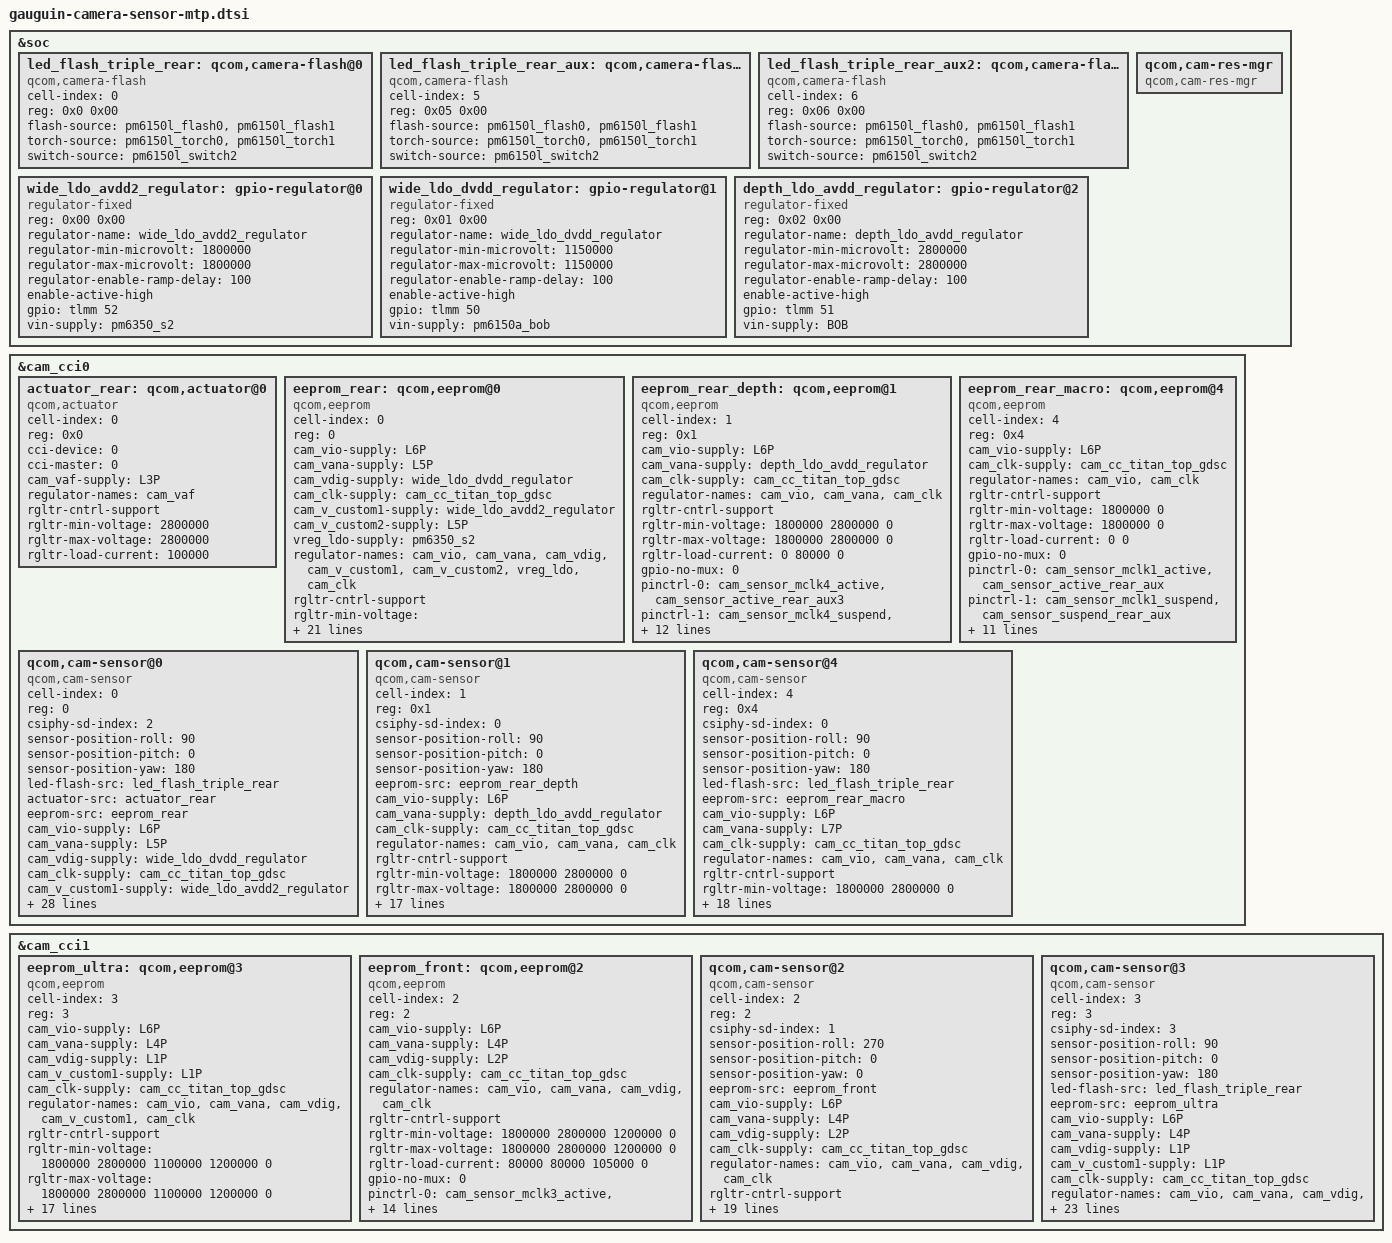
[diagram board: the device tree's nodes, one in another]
#include <dt-bindings/clock/qcom,camcc-lagoon.h>

&soc {
	led_flash_triple_rear: qcom,camera-flash@0 {
		cell-index = <0>;
		reg = <0x0 0x00>;
		compatible = "qcom,camera-flash";
		flash-source = <&pm6150l_flash0 &pm6150l_flash1>;
		torch-source = <&pm6150l_torch0 &pm6150l_torch1>;
		switch-source = <&pm6150l_switch2>;
	};

	led_flash_triple_rear_aux: qcom,camera-flash@5 {
		cell-index = <5>;
		reg = <0x05 0x00>;
		compatible = "qcom,camera-flash";
		flash-source = <&pm6150l_flash0 &pm6150l_flash1>;
		torch-source = <&pm6150l_torch0 &pm6150l_torch1>;
		switch-source = <&pm6150l_switch2>;
	};

	led_flash_triple_rear_aux2: qcom,camera-flash@6 {
		cell-index = <6>;
		reg = <0x06 0x00>;
		compatible = "qcom,camera-flash";
		flash-source = <&pm6150l_flash0 &pm6150l_flash1>;
		torch-source = <&pm6150l_torch0 &pm6150l_torch1>;
		switch-source = <&pm6150l_switch2>;
	};
	wide_ldo_avdd2_regulator: gpio-regulator@0 { //AVDD2 1.8V
		compatible = "regulator-fixed";
		reg = <0x00 0x00>;
		regulator-name = "wide_ldo_avdd2_regulator";
		regulator-min-microvolt = <1800000>;
		regulator-max-microvolt = <1800000>;
		regulator-enable-ramp-delay = <100>;
		enable-active-high;
		gpio = <&tlmm 52 0>;
		vin-supply = <&pm6350_s2>;//64M
	};
	wide_ldo_dvdd_regulator: gpio-regulator@1 { //DVDD 1.1V
		compatible = "regulator-fixed";
		reg = <0x01 0x00>;
		regulator-name = "wide_ldo_dvdd_regulator";
		regulator-min-microvolt = <1150000>;
		regulator-max-microvolt = <1150000>;
		regulator-enable-ramp-delay = <100>;
		enable-active-high;
		gpio = <&tlmm 50 0>;
		vin-supply = <&pm6150a_bob>;//64M
	};

	depth_ldo_avdd_regulator: gpio-regulator@2 { //depth AVDD 2.8V
		compatible = "regulator-fixed";
		reg = <0x02 0x00>;
		regulator-name = "depth_ldo_avdd_regulator";
		regulator-min-microvolt = <2800000>;
		regulator-max-microvolt = <2800000>;
		regulator-enable-ramp-delay = <100>;
		enable-active-high;
		gpio = <&tlmm 51 0>;
		vin-supply = <&BOB>;
	};

	qcom,cam-res-mgr {
		compatible = "qcom,cam-res-mgr";
		status = "ok";
	};
};

&cam_cci0 {
	actuator_rear: qcom,actuator@0 {
		cell-index = <0>;
		reg = <0x0>;
		compatible = "qcom,actuator";
		cci-device = <0>;
		cci-master = <0>;
		cam_vaf-supply = <&L3P>;
		regulator-names = "cam_vaf";
		rgltr-cntrl-support;
		rgltr-min-voltage = <2800000>;
		rgltr-max-voltage = <2800000>;
		rgltr-load-current = <100000>;
		status = "ok";
	};

	eeprom_rear: qcom,eeprom@0 {
		cell-index = <0>;
		reg = <0>;
		compatible = "qcom,eeprom";
		cam_vio-supply = <&L6P>;
		cam_vana-supply = <&L5P>;// AVDD 2.9V
		cam_vdig-supply = <&wide_ldo_dvdd_regulator>;
		cam_clk-supply = <&cam_cc_titan_top_gdsc>;
		cam_v_custom1-supply = <&wide_ldo_avdd2_regulator>;  //AVDD2 1.8V
		cam_v_custom2-supply = <&L5P>;  //AVDD 2.8V
                vreg_ldo-supply = <&pm6350_s2>; //npc ldo input 1.95v
		regulator-names = "cam_vio", "cam_vana", "cam_vdig",
			  "cam_v_custom1","cam_v_custom2","vreg_ldo","cam_clk";
		rgltr-cntrl-support;
		//pwm-switch;
		rgltr-min-voltage = <1800000 2900000 1150000 1800000 2800000 1950000 0>;
		rgltr-max-voltage = <1800000 2900000 1150000 1800000 2800000 2000000 0>;
		rgltr-load-current = <0 2000000 105000 80000 105000 120000 0>;
		gpio-no-mux = <0>;
		pinctrl-names = "cam_default", "cam_suspend";
		pinctrl-0 = <&cam_sensor_mclk0_active
				&cam_sensor_active_rear>;
		pinctrl-1 = <&cam_sensor_mclk0_suspend
				&cam_sensor_suspend_rear>;
		gpios = <&tlmm 29 0>,
			<&tlmm 34 0>;
		gpio-reset = <1>;
		gpio-req-tbl-num = <0 1>;
		gpio-req-tbl-flags = <1 0>;
		gpio-req-tbl-label = "CAMIF_MCLK0",
					"CAM_RESET0";
		sensor-mode = <0>;
		cci-device = <0>;
		cci-master = <0>;
		status = "ok";
		clocks = <&camcc CAM_CC_MCLK0_CLK>;
		clock-names = "cam_clk";
		clock-cntl-level = "turbo";
		clock-rates = <19200000>;
	};
    eeprom_rear_depth: qcom,eeprom@1 { //2M Depth
		cell-index = <1>;
		compatible = "qcom,eeprom";
		reg = <0x1>;
		cam_vio-supply = <&L6P>;
		cam_vana-supply = <&depth_ldo_avdd_regulator>;
		cam_clk-supply = <&cam_cc_titan_top_gdsc>;
		regulator-names = "cam_vio", "cam_vana",
			"cam_clk";
		rgltr-cntrl-support;
		//pwm-switch;
		rgltr-min-voltage = <1800000 2800000 0>;
		rgltr-max-voltage = <1800000 2800000 0>;
		rgltr-load-current = <0 80000 0>;
		gpio-no-mux = <0>;
		pinctrl-names = "cam_default", "cam_suspend";
		pinctrl-0 = <&cam_sensor_mclk4_active
				&cam_sensor_active_rear_aux3>;
		pinctrl-1 = <&cam_sensor_mclk4_suspend
				&cam_sensor_suspend_rear_aux3>;
		gpios = <&tlmm 33 0>,
			<&tlmm 38 0>;
		gpio-reset = <1>;
		gpio-req-tbl-num = <0 1>;
		gpio-req-tbl-flags = <1 0>;
		gpio-req-tbl-label = "CAMIF_MCLK4",
					"CAM_RESET4";
		sensor-mode = <0>;
		cci-device = <0>;
		cci-master = <1>;
		status = "ok";
		clocks = <&camcc CAM_CC_MCLK4_CLK>;
		clock-names = "cam_clk";
		clock-cntl-level = "turbo";
		clock-rates = <19200000>;
	};
	eeprom_rear_macro: qcom,eeprom@4 {
		cell-index = <4>;
		reg = <0x4>;
		compatible = "qcom,eeprom";
		cam_vio-supply = <&L6P>;
		//cam_vana-supply = <&L7P>;
		//cam_vdig-supply = <&L1P>;
		cam_clk-supply = <&cam_cc_titan_top_gdsc>;
		//cam_vaf-supply = <&L5P>;
		regulator-names = "cam_vio",
			"cam_clk";
		rgltr-cntrl-support;
		rgltr-min-voltage = <1800000 0>;
		rgltr-max-voltage = <1800000 0>;
		rgltr-load-current = <0 0>;
		gpio-no-mux = <0>;
		pinctrl-names = "cam_default", "cam_suspend";
		pinctrl-0 = <&cam_sensor_mclk1_active
				&cam_sensor_active_rear_aux>;
		pinctrl-1 = <&cam_sensor_mclk1_suspend
				&cam_sensor_suspend_rear_aux>;
		gpios = <&tlmm 30 0>,
			<&tlmm 35 0>;
		gpio-reset = <1>;
		gpio-req-tbl-num = <0 1>;
		gpio-req-tbl-flags = <1 0>;
		gpio-req-tbl-label = "CAMIF_MCLK1",
					"CAM_RESET1";
		sensor-mode = <0>;
		cci-device = <0>;
		cci-master = <0>;
		status = "ok";
		clocks = <&camcc CAM_CC_MCLK1_CLK>;
		clock-names = "cam_clk";
		clock-cntl-level = "turbo";
		clock-rates = <19200000>;
	};

	qcom,cam-sensor@0 { // Main
		cell-index = <0>;
		compatible = "qcom,cam-sensor";
		reg = <0>;
		csiphy-sd-index = <2>;
		sensor-position-roll = <90>;
		sensor-position-pitch = <0>;
		sensor-position-yaw = <180>;
		led-flash-src = <&led_flash_triple_rear>;
		actuator-src = <&actuator_rear>;
		eeprom-src = <&eeprom_rear>;
		cam_vio-supply = <&L6P>;
		cam_vana-supply = <&L5P>;// AVDD 2.9V
		cam_vdig-supply = <&wide_ldo_dvdd_regulator>;
		cam_clk-supply = <&cam_cc_titan_top_gdsc>;
		cam_v_custom1-supply = <&wide_ldo_avdd2_regulator>;  //AVDD2 1.8V
		cam_v_custom2-supply = <&L5P>;  //AVDD 2.8V
                vreg_ldo-supply = <&pm6350_s2>; //npc ldo input 1.95v
		regulator-names = "cam_vio", "cam_vana", "cam_vdig",
			  "cam_v_custom1","cam_v_custom2","vreg_ldo","cam_clk";
		rgltr-cntrl-support;
		//pwm-switch;
		rgltr-min-voltage = <1800000 2900000 1150000 1800000 2800000 1950000 0>;
		rgltr-max-voltage = <1800000 2900000 1150000 1800000 2800000 2000000 0>;
		rgltr-load-current = <0 2000000 105000 80000 105000 120000 0>;
		gpio-no-mux = <0>;
		pinctrl-names = "cam_default", "cam_suspend";
		pinctrl-0 = <&cam_sensor_mclk0_active
				&cam_sensor_active_rear>;
		pinctrl-1 = <&cam_sensor_mclk0_suspend
				&cam_sensor_suspend_rear>;
		gpios = <&tlmm 29 0>,
			<&tlmm 34 0>;
		gpio-reset = <1>;
		gpio-req-tbl-num = <0 1>;
		gpio-req-tbl-flags = <1 0>;
		gpio-req-tbl-label = "CAMIF_MCLK0",
					"CAM_RESET0";
		sensor-mode = <0>;
		cci-device = <0>;
		cci-master = <0>;
		status = "ok";
		clocks = <&camcc CAM_CC_MCLK0_CLK>;
		clock-names = "cam_clk";
		clock-cntl-level = "turbo";
		clock-rates = <19200000>;
	};

	qcom,cam-sensor@1 { //2M Depth
		cell-index = <1>;
		compatible = "qcom,cam-sensor";
		reg = <0x1>;
		csiphy-sd-index = <0>;
		sensor-position-roll = <90>;
		sensor-position-pitch = <0>;
		sensor-position-yaw = <180>;
		//led-flash-src = <&led_flash_triple_rear_aux>;
		//actuator-src = <&actuator_triple_rear_aux>;
		eeprom-src = <&eeprom_rear_depth>;
		cam_vio-supply = <&L6P>;
		cam_vana-supply = <&depth_ldo_avdd_regulator>;
		cam_clk-supply = <&cam_cc_titan_top_gdsc>;
		regulator-names = "cam_vio", "cam_vana",
			"cam_clk";
		rgltr-cntrl-support;
		//pwm-switch;
		rgltr-min-voltage = <1800000 2800000 0>;
		rgltr-max-voltage = <1800000 2800000 0>;
		rgltr-load-current = <0 80000 0>;
		gpio-no-mux = <0>;
		pinctrl-names = "cam_default", "cam_suspend";
		pinctrl-0 = <&cam_sensor_mclk4_active
				&cam_sensor_active_rear_aux3>;
		pinctrl-1 = <&cam_sensor_mclk4_suspend
				&cam_sensor_suspend_rear_aux3>;
		gpios = <&tlmm 33 0>,
			<&tlmm 38 0>;
		gpio-reset = <1>;
		gpio-req-tbl-num = <0 1>;
		gpio-req-tbl-flags = <1 0>;
		gpio-req-tbl-label = "CAMIF_MCLK4",
					"CAM_RESET4";
		sensor-mode = <0>;
		cci-device = <0>;
		cci-master = <1>;
		status = "ok";
		clocks = <&camcc CAM_CC_MCLK4_CLK>;
		clock-names = "cam_clk";
		clock-cntl-level = "turbo";
		clock-rates = <19200000>;
	};

	qcom,cam-sensor@4 { //For Macro
		cell-index = <4>;
		compatible = "qcom,cam-sensor";
		reg = <0x4>;
		csiphy-sd-index = <0>;
		sensor-position-roll = <90>;
		sensor-position-pitch = <0>;
		sensor-position-yaw = <180>;
		led-flash-src = <&led_flash_triple_rear>;
		//actuator-src = <&actuator_triple_rear_aux>;
		eeprom-src = <&eeprom_rear_macro>;
		cam_vio-supply = <&L6P>;
		cam_vana-supply = <&L7P>;
		//cam_vdig-supply = <&L1P>;
		cam_clk-supply = <&cam_cc_titan_top_gdsc>;
		regulator-names = "cam_vio", "cam_vana",
			"cam_clk";
		rgltr-cntrl-support;
		//pwm-switch;
		rgltr-min-voltage = <1800000 2800000 0>;
		rgltr-max-voltage = <1800000 2800000 0>;
		rgltr-load-current = <0 2000000 0>;
		gpio-no-mux = <0>;
		pinctrl-names = "cam_default", "cam_suspend";
		pinctrl-0 = <&cam_sensor_mclk1_active
			&cam_sensor_active_rear_aux>;
		pinctrl-1 = <&cam_sensor_mclk1_suspend
			&cam_sensor_suspend_rear_aux>;
		gpios = <&tlmm 30 0>,
			<&tlmm 35 0>;
		gpio-reset = <1>;
		gpio-req-tbl-num = <0 1>;
		gpio-req-tbl-flags = <1 0>;
		gpio-req-tbl-label = "CAMIF_MCLK1",
					"CAM_RESET1";
		sensor-mode = <0>;
		cci-device = <0>;
		cci-master = <0>;
		status = "ok";
		clocks = <&camcc CAM_CC_MCLK1_CLK>;
		clock-names = "cam_clk";
		clock-cntl-level = "turbo";
		clock-rates = <19200000>;
	};
};

&cam_cci1 {
	eeprom_ultra: qcom,eeprom@3 {
		cell-index = <3>;
		reg = <3>;
		compatible = "qcom,eeprom";
		cam_vio-supply = <&L6P>;
		cam_vana-supply = <&L4P>;
		cam_vdig-supply = <&L1P>;
                cam_v_custom1-supply = <&L1P>;
		cam_clk-supply = <&cam_cc_titan_top_gdsc>;
		regulator-names = "cam_vio", "cam_vana", "cam_vdig",
			   "cam_v_custom1", "cam_clk";
		rgltr-cntrl-support;
		 //pwm-switch;
		rgltr-min-voltage = <1800000 2800000 1100000 1200000 0>;
		rgltr-max-voltage = <1800000 2800000 1100000 1200000 0>;
		rgltr-load-current = <0 2000000 105000 105000 0>;
		gpio-no-mux = <0>;
		pinctrl-names = "cam_default", "cam_suspend";
		pinctrl-0 = <&cam_sensor_mclk2_active
			   &cam_sensor_active_rear_aux2>;
		pinctrl-1 = <&cam_sensor_mclk2_suspend
			   &cam_sensor_suspend_rear_aux2>;
		gpios = <&tlmm 31 0>,
			  <&tlmm 36 0>;
		gpio-reset = <1>;
		gpio-req-tbl-num = <0 1>;
		gpio-req-tbl-flags = <1 0>;
		gpio-req-tbl-label = "CAMIF_MCLK2",
					"CAM_RESET2";
		sensor-mode = <0>;
		cci-device = <1>;
		cci-master = <0>;
		status = "ok";
		clocks = <&camcc CAM_CC_MCLK2_CLK>;
		clock-names = "cam_clk";
		clock-cntl-level = "turbo";
		clock-rates = <19200000>;
	};
	eeprom_front: qcom,eeprom@2 {
		cell-index = <2>;
		reg = <2>;
		compatible = "qcom,eeprom";
		cam_vio-supply = <&L6P>;
		cam_vana-supply = <&L4P>;
		cam_vdig-supply = <&L2P>;
		cam_clk-supply = <&cam_cc_titan_top_gdsc>;
		regulator-names = "cam_vio", "cam_vana", "cam_vdig",
			   "cam_clk";
		rgltr-cntrl-support;
		 //pwm-switch;
		rgltr-min-voltage = <1800000 2800000 1200000 0>;
		rgltr-max-voltage = <1800000 2800000 1200000 0>;
		rgltr-load-current = <80000 80000 105000 0>;
		gpio-no-mux = <0>;
		pinctrl-names = "cam_default", "cam_suspend";
		pinctrl-0 = <&cam_sensor_mclk3_active
			   &cam_sensor_active_front>;
		pinctrl-1 = <&cam_sensor_mclk3_suspend
			   &cam_sensor_suspend_front>;
		gpios = <&tlmm 32 0>,
			  <&tlmm 37 0>;
		gpio-reset = <1>;
		gpio-req-tbl-num = <0 1>;
		gpio-req-tbl-flags = <1 0>;
		gpio-req-tbl-label = "CAMIF_MCLK3",
					"CAM_RESET3";
		sensor-mode = <0>;
		cci-device = <1>;
		cci-master = <0>;
		status = "ok";
		clocks = <&camcc CAM_CC_MCLK3_CLK>;
		clock-names = "cam_clk";
		clock-cntl-level = "turbo";
		clock-rates = <19200000>;
	};
	qcom,cam-sensor@2 { //16M FRONT
		cell-index = <2>;
		compatible = "qcom,cam-sensor";
		reg = <2>;
		csiphy-sd-index = <1>;
		sensor-position-roll = <270>;
		sensor-position-pitch = <0>;
		sensor-position-yaw = <0>;
		//led-flash-src = <&led_flash_triple_rear_aux>;
		//actuator-src = <&actuator_triple_rear_aux>;
		eeprom-src = <&eeprom_front>;
		cam_vio-supply = <&L6P>;
		cam_vana-supply = <&L4P>;
		cam_vdig-supply = <&L2P>;
		cam_clk-supply = <&cam_cc_titan_top_gdsc>;
		regulator-names = "cam_vio", "cam_vana", "cam_vdig",
			   "cam_clk";
		rgltr-cntrl-support;
		 //pwm-switch;
		rgltr-min-voltage = <1800000 2800000 1200000 0>;
		rgltr-max-voltage = <1800000 2800000 1200000 0>;
		rgltr-load-current = <80000 80000 105000 0>;
		gpio-no-mux = <0>;
		pinctrl-names = "cam_default", "cam_suspend";
		pinctrl-0 = <&cam_sensor_mclk3_active
			   &cam_sensor_active_front>;
		pinctrl-1 = <&cam_sensor_mclk3_suspend
			   &cam_sensor_suspend_front>;
		gpios = <&tlmm 32 0>,
			  <&tlmm 37 0>;
		gpio-reset = <1>;
		gpio-req-tbl-num = <0 1>;
		gpio-req-tbl-flags = <1 0>;
		gpio-req-tbl-label = "CAMIF_MCLK3",
					"CAM_RESET3";
		sensor-mode = <0>;
		cci-device = <1>;
		cci-master = <0>;
		status = "ok";
		clocks = <&camcc CAM_CC_MCLK3_CLK>;
		clock-names = "cam_clk";
		clock-cntl-level = "turbo";
		clock-rates = <19200000>;
	};

	qcom,cam-sensor@3 { //8M
		cell-index = <3>;
		compatible = "qcom,cam-sensor";
		reg = <3>;
		csiphy-sd-index = <3>;
		sensor-position-roll = <90>;
		sensor-position-pitch = <0>;
		sensor-position-yaw = <180>;
		led-flash-src = <&led_flash_triple_rear>;
		//actuator-src = <&actuator_triple_rear_aux>;
		eeprom-src = <&eeprom_ultra>;
		cam_vio-supply = <&L6P>;
		cam_vana-supply = <&L4P>;
		cam_vdig-supply = <&L1P>;
                cam_v_custom1-supply = <&L1P>;
		cam_clk-supply = <&cam_cc_titan_top_gdsc>;
		regulator-names = "cam_vio", "cam_vana", "cam_vdig",
			   "cam_v_custom1", "cam_clk";
		rgltr-cntrl-support;
		 //pwm-switch;
		rgltr-min-voltage = <1800000 2800000 1200000 1200000 0>;
		rgltr-max-voltage = <1800000 2800000 1200000 1200000 0>;
		rgltr-load-current = <0 2000000 105000 105000 0>;
		gpio-no-mux = <0>;
		pinctrl-names = "cam_default", "cam_suspend";
		pinctrl-0 = <&cam_sensor_mclk2_active
			   &cam_sensor_active_rear_aux2>;
		pinctrl-1 = <&cam_sensor_mclk2_suspend
			   &cam_sensor_suspend_rear_aux2>;
		gpios = <&tlmm 31 0>,
			  <&tlmm 36 0>;
		gpio-reset = <1>;
		gpio-req-tbl-num = <0 1>;
		gpio-req-tbl-flags = <1 0>;
		gpio-req-tbl-label = "CAMIF_MCLK2",
					"CAM_RESET2";
		sensor-mode = <0>;
		cci-device = <1>;
		cci-master = <0>;
		status = "ok";
		clocks = <&camcc CAM_CC_MCLK2_CLK>;
		clock-names = "cam_clk";
		clock-cntl-level = "turbo";
		clock-rates = <19200000>;
	};
};
